# SAM9X75D5MN0 device description
Architecture: ARM926EJ-S; Family: SAM9; Series: SAM9X7
Registers are 32-bit, read-write, reset 0x0 unless marked. A register's access mark holds for its fields unless they carry their own. Offsets are from the block's base; [hi:lo] are bit positions; {n}, {i} and the like mark numbered series.

## PUF — Physical Unclonable Functions
Instances: PUF 0xF8030000
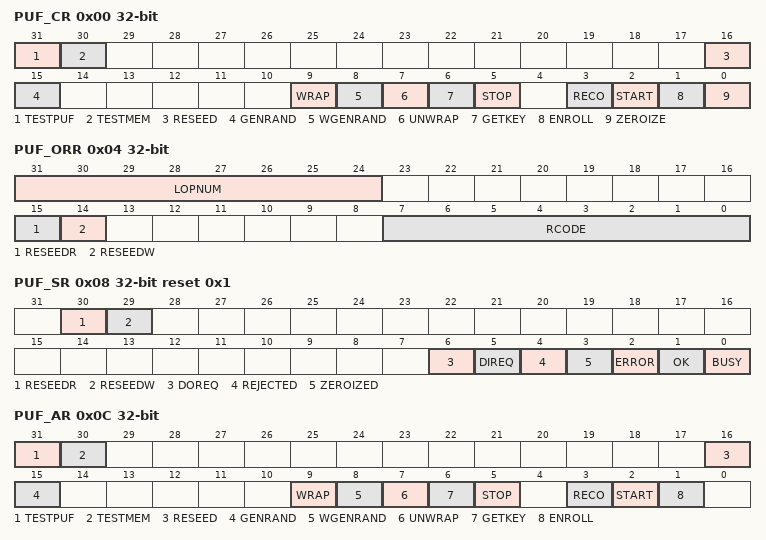
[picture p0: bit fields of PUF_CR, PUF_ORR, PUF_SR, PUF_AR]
0x00 PUF_CR — Control Register
  [31] TESTPUF — Test PUF Operation
  [30] TESTMEM — Test Memory Operation
  [16] RESEED — Reseed Operation
  [15] GENRAND — Generate Random Operation
  [9] WRAP — Wrap Operation
  [8] WGENRAND — Wrap Generated Random Operation
  [7] UNWRAP — Unwrap Operation
  [6] GETKEY — Get Key Operation
  [5] STOP — Stop Operation
  [3] RECO — Reconstruct Operation
  [2] START — Start Operation
  [1] ENROLL — Enroll Operation
  [0] ZEROIZE — Zeroize Operation
0x04 PUF_ORR ro — Operation Result Register
  [31:24] LOPNUM — Last Operation Number
    0=IID_PUF_LO_PROGRESS (An operation is in progress.); 1=IID_PUF_LO_ENROLL (The last operation was ENROLL.); 2=IID_PUF_LO_START (The last operation was START.); 3=IID_PUF_LO_RECONSTRUCT (The last operation was RECONSTRUCT.); 5=IID_PUF_LO_STOP (The last operation was STOP.); 6=IID_PUF_LO_GET_KEY (The last operation was GET KEY.); 7=IID_PUF_LO_UNWRAP (The last operation was UNWRAP.); 8=IID_PUF_LO_WRAP_GEN_RND (The last operation was WRAP GENERATED RANDOM.); 9=IID_PUF_LO_WRAP (The last operation was WRAP.); 15=IID_PUF_LO_GEN_RND (The last operation was GENERATED RANDOM.); 16=IID_PUF_LO_RESEED (The last operation was RESEED.); 30=IID_PUF_LO_TEST_MEMORY (The last operation was TESTMEMORY.); 31=IID_PUF_LO_TEST_PUF (The last operation was TESTPUF.); 32=IID_PUF_LO_INITIALIZATION (The last operation was INITIALIZATION.); 47=IID_PUF_LO_ZEROIZE (The last operation was ZEROIZE.)
  [15] RESEEDR — Reseed Required
    0=NO_ACTION (No action required.); 1=REQUIRED_ACTION (The maximum number of DRBG2 requests has been done. A reseed must be performed before other operations can be done. This bit is the same as in PUF_SR.)
  [14] RESEEDW — Reseed Warning
    0=NO_ACTION (No action required.); 1=RECOMMENDED_ACTION (The DRBG reseed counter is close to its limit, it is recommended to reseed at the first suitable moment. This bit is the same as in PUF_SR.)
  [7:0] RCODE — Last Operation Result Code
    0=IID_PUF_OK (The last operation was successful or an operation is in progress.); 240=IID_PUF_ERR_PRODUCT (The provided activation code is not correct.); 241=IID_PUF_ERR_PRODUCT_PH2 (The activation code in the second phase is not correct.); 242=IID_PUF_ERR_TRANSFER (The provided activation code is corrupted.); 243=IID_PUF_ERR_TRANSFER_PH2 (The activation code in the second phase is corrupted.); 244=IID_PUF_ERR_AUTH (Authentication of the provided activation code failed.); 245=IID_PUF_ERR_AUTH_PH2 (Authentication of the provided activation code failed in the second phase.); 246=IID_PUF_ERR_PUF_QUALITY (Dedicated Embedded Static RAM PUF quality verification fails.); 247=IID_PUF_ERR_CONTEXT (An incorrect or unsupported context is provided.); 248=IID_PUF_ERR_DESTINATION (A data destination that was set is not allowed according to other settings and the current PUF state.); 251=IID_PUF_FAILURE_DRBG2_ENTROPY (DRBG2 Reseed or Instantiation failed (DRBG1 cannot provide entropy).); 252=IID_PUF_FAILURE_DRBG1_ENTROPY (The entropy test for DRBG1 failed.); 253=IID_PUF_FAILURE_DRBG_HEALTH (One or more of the DRBG health tests failed.); 254=IID_PUF_FAILURE_SETTINGS (Initialization cannot finish due to illegal values in PUF_HW_SETTINGS.); 255=IID_PUF_FAILURE_SRAM (PUF SRAM access has failed.)
0x08 PUF_SR reset 0x1 — Status Register
  [30] RESEEDR — Reseed Required
    0=NO_ACTION (No action required.); 1=REQUIRED_ACTION (The maximum number of DRBG2 requests has been done. A reseed must be performed before other operations can be done. This bit is the same as in PUF_ORR.)
  [29] RESEEDW — Reseed Warning
    0=NO_ACTION (No action required.); 1=RECOMMENDED_ACTION (The reseed counter of the DRBG is close to its limit, it is recommended to reseed at the first suitable moment. This bit is the same as in PUF_ORR.)
  [6] DOREQ — Data Out Request Status
    0=No data-out transfer is in progress; 1=A data-out transfer is in progress following a request via PUF_DOR
  [5] DIREQ — Data In Request Status
    0=No data-in transfer is in progress; 1=A data-in transfer is in progress following a request via PUF_DIR
  [4] REJECTED — Last Command Rejection Status (cleared by writing a 1)
    0=No rejection event occurred since the last clearing access; 1=A rejection event occurred when the last command has been launched. Cleared by writing a 1.
  [3] ZEROIZED — PUF Zeroization in Progress
    0=No zeroization is in progress; 1=A zeroization action is in progress or the PUF is in Locked state
  [2] ERROR — Last Operation Failed
    0=The last operation completed successfully; 1=The last operation failed
  [1] OK — Last Operation Successfully Achieved
    0=ERROR bit must be checked; 1=The last operation completed successfully
  [0] BUSY — Operation in Progress
    0=No operation is in progress. A new operation can be initiated.; 1=An operation is in progress. No new operation must be launched.
0x0C PUF_AR ro — Allow Register
  [31] TESTPUF — Test PUF Operation
  [30] TESTMEM — Test Memory Operation
  [16] RESEED — Reseed Operation
  [15] GENRAND — Generate Random Operation
  [9] WRAP — Wrap Operation
  [8] WGENRAND — Wrap Generated Random Operation
  [7] UNWRAP — Unwrap Operation
  [6] GETKEY — Get Key Operation
  [5] STOP — Stop Operation
  [3] RECO — Reconstruct Operation
  [2] START — Start Operation
  [1] ENROLL — Enroll Operation
0x10 PUF_IER (atomic set of PUF_IMR) — Interrupt Enable Register
  [0] INTEN — Interruption Enable
    0=Disables the interruption; 1=Enables the PUF to trigger an interruption from the sources selected in PUF_IMR
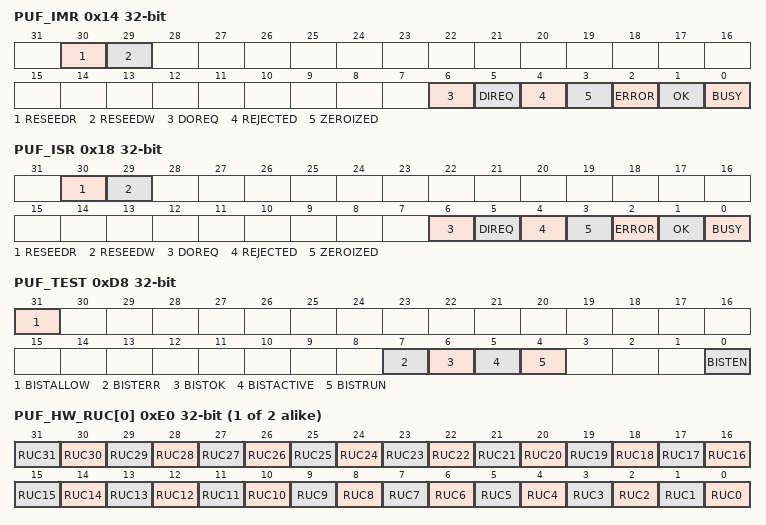
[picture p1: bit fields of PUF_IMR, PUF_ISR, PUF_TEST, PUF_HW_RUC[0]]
0x14 PUF_IMR — Interrupt Mask Register
  [30] RESEEDR — Reseed Action Required Event
  [29] RESEEDW — Reseed Warning Event
  [6] DOREQ — Data Out Request Event
  [5] DIREQ — Data In Request Event
  [4] REJECTED — Last Activation Code Rejection Event
  [3] ZEROIZED — Zeroized Operation Completed Event
  [2] ERROR — Last Operation Fail Event
  [1] OK — Last Operation Successful Achievement Event
  [0] BUSY — Operation Start Event
0x18 PUF_ISR — Interrupt Status Register
  [30] RESEEDR — Reseed Action Required (cleared by writing a 1)
  [29] RESEEDW — Reseed Warning (cleared by writing a 1)
  [6] DOREQ — Data Out Request (cleared by writing a 1)
  [5] DIREQ — Data In Request (cleared by writing a 1)
  [4] REJECTED — Last Activation Code Rejection (cleared by writing a 1)
  [3] ZEROIZED — Zeroized Operation Completed (cleared by writing a 1)
  [2] ERROR — Last Operation Fail (cleared by writing a 1)
  [1] OK — Last Operation Achievement (cleared by writing a 1)
  [0] BUSY — Operation in Progress (cleared by writing a 1)
0x20 PUF_DATA_DEST — Data Destination Register
  [0] DO — Data Output on PUF_DOR
    0=DISABLED (PUF_DOR cannot be used to read data from PUF operations.); 1=DO_VIA_DOR (PUF_DOR is enabled to read data from PUF operations.)
0x24 PUF_DATA_SRC — Data Source Register
  [0] DI — Data Input Loaded from PUF_DIR
    0=DISABLED (PUF_DIR cannot be used to transfer data to PUF.); 1=DI_VIA_DIR (PUF_DIR is enabled to load data to PUF.)
0x28 PUF_KEY_INDEX ro — Key Index Register
  [3:0] KI — Key Index
0xA0 PUF_DIR wo reset not defined — Data Input Register
  [31:0] DI — Data Input Value
0xA8 PUF_DOR ro — Data Output Register
  [31:0] DO — Data Output Value
0xC0 PUF_MISC reset 0x1 — Miscellaneous Register
  [0] DEND — Data Endianness
    0=LITTLE (Little-endian mode.); 1=BIG (Big-endian mode. This is the default value.)
0xD0 PUF_IF_SR — Interface Status Register
  [0] BUSERR — Bus Access Error (cleared by writing a 1)
    0=NONE (No incorrect access performed since the last write access (BUSERR=1).); 1=ERROR (An incorrect access has been performed. Cleared by writing a 1.)
0xD8 PUF_TEST — Test Register
  [31] BISTALLOW — Built-In Self-Test Allowed
    0=BIST Start (BISTEN) command is disabled and has no effect; 1=BIST Start command (BISTEN) is allowed
  [7] BISTERR — Built-In Self-Test Error
    0=No action; 1=If BISTRUN=1 and BISTACTIVE=0, BIST has failed
  [6] BISTOK — Built-In Self-Test Run Passed
    0=No action; 1=If BISTRUN=1 and BISTACTIVE=0, BIST has passed successfully
  [5] BISTACTIVE — Built-In Self-Test Activity Status
    0=BIST has completed if BISTRUN=1; 1=If BISTRUN=1, BIST is in progress
  [4] BISTRUN — Built-In Self-Test Run Status
    0=BIST is not active or has not started yet; 1=BIST is enabled
  [0] BISTEN — Built-In Self-Test Enable
    0=Disables the BIST, must be performed once BIST completion event occurred (BISTOK=1); 1=Starts the BIST
0xDC PUF_PSR ro reset 0xF — Score Register
  [3:0] SCORE — Last Test Score
{0xE0+4i} PUF_HW_RUC[{i}] (i=0..1) ro — Hardware Restrict User Context x Register
  [all] fields
    0=This bit can be used in the user context 0 field; 1=This bit cannot be used in the user context 0 field
  [n] RUC{n} (n=0..31) — Restrict User Context Bit {n}
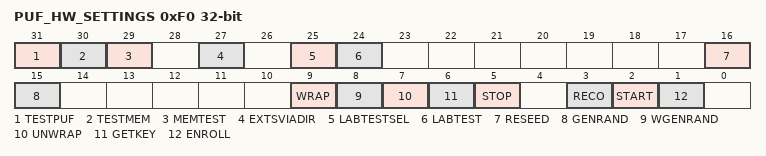
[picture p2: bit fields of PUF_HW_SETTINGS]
0xF0 PUF_HW_SETTINGS ro reset not defined — Hardware Settings Register
  [31] TESTPUF — Test PUF Operation
  [30] TESTMEM — Test Memory Operation
  [29] MEMTEST — Memory Tests Included in Initialization
  [27] EXTSVIADIR — External Entropy Required via PUF_DIR During Reseed Operation
  [25] LABTESTSEL — Selection of Lab Test Mode, when LABTEST=0
  [24] LABTEST — Initialization to Lab Test Mode
  [16] RESEED — Reseed Operation
  [15] GENRAND — Generate Random Operation
  [9] WRAP — Wrap Operation
  [8] WGENRAND — Wrap Generated Random Operation
  [7] UNWRAP — Unwrap Operation
  [6] GETKEY — Get Key Operation
  [5] STOP — Stop Operation
  [3] RECO — Reconstruct Operation
  [2] START — Start Operation
  [1] ENROLL — Enroll Operation
